VERSION ""

NS_ :

BS_:

BU_: ADAS

BO_ 3221225472 VECTOR__INDEPENDENT_SIG_MSG: 0 Vector__XXX
 SG_ Target_Vehicle_PosX : 0|12@1+ (0.0625,0) [0|255.9375] "m" Vector__XXX
 SG_ CAN_VIS_OBS_TTC_WITH_ACC : 0|10@1+ (0.01,0) [0|10.23] "s" Vector__XXX

BO_ 2365443122 OEL: 8 Vector__XXX
 SG_ TurnSignalSwitch : 8|4@1+ (1,0) [0|15] ""  ADAS

BO_ 2561271858 FLIC: 8 Vector__XXX
 SG_ FCWSystemEnableCommand : 2|2@1+ (1,0) [0|3] ""  ADAS
 SG_ LDWEnableCommand : 0|2@1+ (1,0) [0|3] ""  ADAS

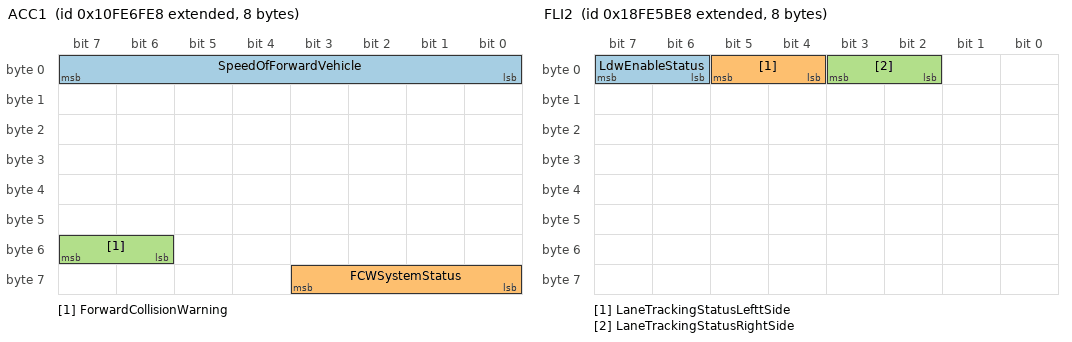
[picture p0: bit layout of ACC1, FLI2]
BO_ 2432593896 ACC1: 8 ADAS
 SG_ SpeedOfForwardVehicle : 0|8@1+ (1,0) [0|250] "km/h" Vector__XXX
 SG_ FCWSystemStatus : 56|4@1+ (1,0) [0|15] "" Vector__XXX
 SG_ ForwardCollisionWarning : 54|2@1+ (1,0) [0|3] "" Vector__XXX

BO_ 2566806504 FLI2: 8 ADAS
 SG_ LdwEnableStatus : 6|2@1+ (1,0) [0|3] "" Vector__XXX
 SG_ LaneTrackingStatusLefttSide : 4|2@1+ (1,0) [0|3] "" Vector__XXX
 SG_ LaneTrackingStatusRightSide : 2|2@1+ (1,0) [0|3] "" Vector__XXX

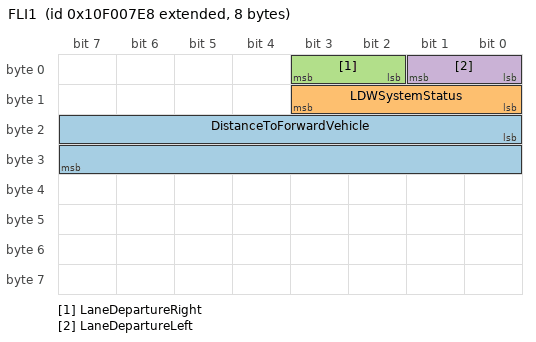
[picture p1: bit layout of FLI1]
BO_ 2431649768 FLI1: 8 ADAS
 SG_ DistanceToForwardVehicle : 16|16@1+ (0.01,0) [0|250] "m" Vector__XXX
 SG_ LDWSystemStatus : 8|4@1+ (1,0) [0|15] "" Vector__XXX
 SG_ LaneDepartureRight : 2|2@1+ (1,0) [0|3] "" Vector__XXX
 SG_ LaneDepartureLeft : 0|2@1+ (1,0) [0|3] "" Vector__XXX

BO_ 2365484270 TCO1: 8 Vector__XXX
 SG_ TachographVehicleSpeed : 48|16@1+ (0.00390625,0) [0|255.996] "km/h"  ADAS

CM_ BO_ 3221225472 "This is a message for not used signals, created by Vector CANdb++ DBC OLE DB Provider.";
BA_DEF_ BO_  "GenMsgCycleTime" INT 2 50000;
BA_DEF_DEF_  "GenMsgCycleTime" 100;
BA_ "GenMsgCycleTime" BO_ 2365443122 200;
BA_ "GenMsgCycleTime" BO_ 2561271858 200;
BA_ "GenMsgCycleTime" BO_ 2431649768 50;
BA_ "GenMsgCycleTime" BO_ 2365484270 50;
VAL_ 2365443122 TurnSignalSwitch 15 "Not available" 14 "Error" 13 "Reserved" 12 "Reserved" 11 "Reserved" 10 "Reserved" 9 "Reserved" 8 "Reserved" 7 "Reserved" 6 "Reserved" 5 "Reserved" 4 "Reserved" 3 "Reserved" 2 "Right turn to be Flashing" 1 "Left Turn to be Flashing" 0 "No Turn being signaled" ;
VAL_ 2561271858 FCWSystemEnableCommand 3 "Don¡ät care" 2 "Reserved" 1 "Enable" 0 "Disable" ;
VAL_ 2561271858 LDWEnableCommand 3 "Don¡ät care" 2 "Reserved" 1 "Enable" 0 "Disable" ;
VAL_ 2432593896 FCWSystemStatus 15 "reserve" 14 "reserve" 13 "reserve" 12 "reserve" 11 "reserve" 10 "reserve" 9 "reserve" 8 "reserve" 7 "reserve" 6 "reserve" 5 "reserve" 4 "reserve" 3 "fault" 2 "No calibration" 1 "Enable" 0 "Disable" ;
VAL_ 2432593896 ForwardCollisionWarning 3 "Description for the value '0x3'" 2 "Level 2 warning" 1 "Level 1 warning" 0 "No warning" ;
VAL_ 2566806504 LdwEnableStatus 3 "Not Use" 2 "Reserved" 1 "enabled" 0 "disabled" ;
VAL_ 2566806504 LaneTrackingStatusLefttSide 3 "Don't Care" 2 "Reserved" 1 "Tracking Left side" 0 "Not Tracking Left side" ;
VAL_ 2566806504 LaneTrackingStatusRightSide 3 "Don't Care" 2 "Reserved" 1 "Tracking Right side" 0 "Not Tracking Right side" ;
VAL_ 2431649768 LDWSystemStatus 15 "reserve" 14 "reserve" 13 "reserve" 12 "reserve" 11 "reserve" 10 "reserve" 9 "reserve" 8 "reserve" 7 "reserve" 6 "reserve" 5 "reserve" 4 "reserve" 3 "camera_fault" 2 "not_calibrated" 1 "System Error" 0 "System Normal" ;
VAL_ 2431649768 LaneDepartureRight 3 "Take no action" 2 "Reserved" 1 "warning" 0 "no warning" ;
VAL_ 2431649768 LaneDepartureLeft 3 "Take no action" 2 "Reserved" 1 "warning" 0 "no warning" ;
